# CM41x_M4 register map
Vendor: Analog Devices; Series: CM41x_M4; File version: 1p0
CPU: CM4 r0p1, little endian, MPU, FPU, 4 interrupt priority bits
Registers are 32-bit, read-write, reset 0x0 unless marked. A register's access mark holds for its fields unless they carry their own. Offsets are from the block's base; [hi:lo] are bit positions; {n}, {i} and the like mark numbered series; 'fields as' and 'values as' point back to an identical list.

## TRACE0 — Trace Port Interface Unit
Base 0xE0040000
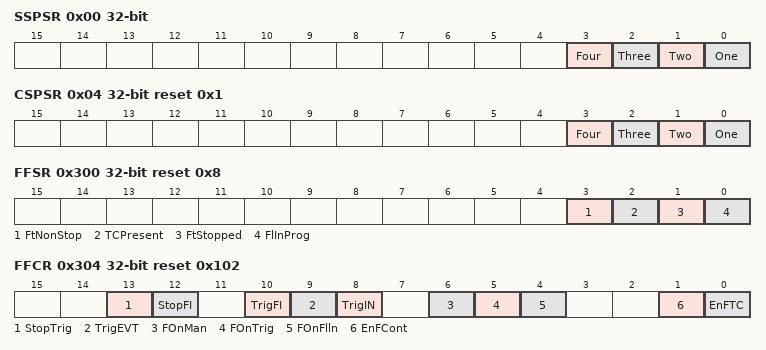
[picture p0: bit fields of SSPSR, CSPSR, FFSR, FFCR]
0x00 SSPSR — Supported Sync Port Sizes Register.
  [3] Four ro — 4-bit port size support
  [2] Three ro — 3-bit port size support
  [1] Two ro — 2-bit port size support
  [0] One ro — 1-bit port size support
0x04 CSPSR reset 0x1 — Current Sync Port Size Register.
  [3] Four range 0x00000000..0x00000001 — 4-bit port enable
  [2] Three range 0x00000000..0x00000001 — 3-bit port enable
  [1] Two range 0x00000000..0x00000001 — 2-bit port enable
  [0] One range 0x00000000..0x00000001 — 1-bit port enable
0x10 ACPR — Async Clock Prescaler Register.
  [12:0] PRESCALER range 0x00000000..0x00001FFF — Divisor for TRACECLKIN is Prescaler + 1.
0xF0 SPPR reset 0x1 — Selected Pin Protocol Register.
  [1:0] PROTOCOL range 0x00000000..0x00000003 — Trace output protocol
0x300 FFSR reset 0x8 — Formatter and Flush Status Register.
  [3] FtNonStop ro — Formatter cannot be stopped
  [2] TCPresent ro — This bit always reads as zero
  [1] FtStopped ro — This bit always reads as zero
  [0] FlInProg ro — This bit always reads as zero
0x304 FFCR reset 0x102 — Formatter and Flush Control Register.
  [13] StopTrig range 0x00000000..0x00000001 — Stop the formatter after a Trigger Event is observed.
  [12] StopFI range 0x00000000..0x00000001 — Stop the formatter after a flush completes.
  [10] TrigFI range 0x00000000..0x00000001 — Indicates a trigger on Flush completion.
  [9] TrigEVT range 0x00000000..0x00000001 — Indicate a trigger on a Trigger Event.
  [8] TrigIN range 0x00000000..0x00000001 — Indicate a trigger on TRIGIN being asserted.
  [6] FOnMan range 0x00000000..0x00000001 — Manually generate a flush of the system.
  [5] FOnTrig range 0x00000000..0x00000001 — Generate flush using Trigger event.
  [4] FOnFlln range 0x00000000..0x00000001 — Generate flush using the FLUSHIN interface.
  [1] EnFCont range 0x00000000..0x00000001 — Continuous Formatting, no TRACECTL.
  [0] EnFTC range 0x00000000..0x00000001 — Enable Formatting.
0x308 FSCR — Formatter Synchronization Counter Register.
  [31:0] VALUE range 0x00000000..0xFFFFFFFF
0xEE8 TRIGGER — Integration Register: TRIGGER.
  [0] TRIGGER_input_value ro — Enables the TRIGGER input
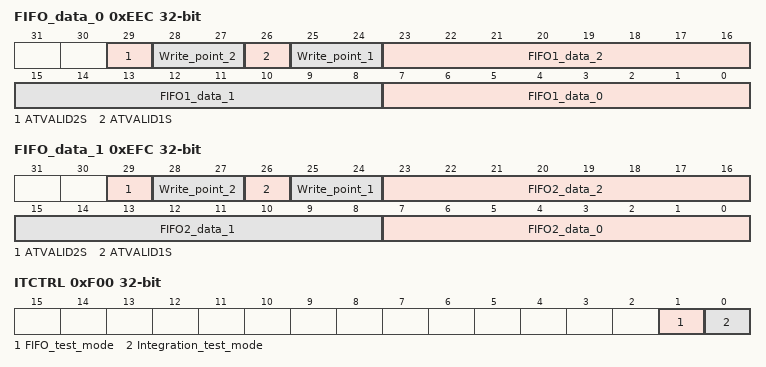
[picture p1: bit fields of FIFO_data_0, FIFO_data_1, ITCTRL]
0xEEC FIFO_data_0 — Integration register: FIFO data 0.
  [29] ATVALID2S ro — Value
  [28:27] Write_point_2 ro
  [26] ATVALID1S ro — Value
  [25:24] Write_point_1 ro
  [23:16] FIFO1_data_2 ro
  [15:8] FIFO1_data_1 ro
  [7:0] FIFO1_data_0 ro
0xEF0 ITATBCTR2 — Integration Register: ITATBCTR2.
  [0] ATREADY1_ATREADY2 ro
0xEF8 ITATBCTR0 — Integration Register: ITATBCTR0.
  [0] ATVALID1_ATVALID2 ro
0xEFC FIFO_data_1 — Integration register: FIFO data 1.
  [29] ATVALID2S ro — Value
  [28:27] Write_point_2 ro
  [26] ATVALID1S ro — Value
  [25:24] Write_point_1 ro
  [23:16] FIFO2_data_2 ro
  [15:8] FIFO2_data_1 ro
  [7:0] FIFO2_data_0 ro
0xF00 ITCTRL — Integration Mode Control Register.
  [1] FIFO_test_mode range 0x00000000..0x00000001 — Enables FIFO test mode
  [0] Integration_test_mode range 0x00000000..0x00000001 — Enables integration test mode
0xFA0 CLAIMSET reset 0xF — Claim tag set register.
  [31:0] VALUE range 0x00000000..0xFFFFFFFF — Claim Tag
0xFA4 CLAIMCLR — Claim tag clear register.
  [31:0] VALUE range 0x00000000..0xFFFFFFFF — Claim Tag
0xFC8 DEVID reset 0xCA1 — Device ID register.
  [31:0] VALUE range 0x00000000..0xFFFFFFFF — Device ID
0xFD0 PID4 reset 0x4 — Peripheral identification register (PID4).
  [31:0] VALUE range 0x00000000..0xFFFFFFFF — Peripheral identification bits
{0xFC0+4i} PID{i} (i=5..7) — Peripheral identification register (PID{i}).
  fields as PID4
0xFE0 PID0 reset 0x23 — Peripheral identification register Bits 7:0 (PID0).
  fields as PID4
0xFE4 PID1 reset 0xB9 — Peripheral identification register Bits 15:8 (PID1).
  fields as PID4
0xFE8 PID2 reset 0x3B — Peripheral identification register Bits 23:16 (PID2).
  fields as PID4
0xFEC PID3 — Peripheral identification register Bits 31:24 (PID3).
  fields as PID4
0xFF0 CID0 reset 0xD — Component identification register Bits 7:0 (CID0).
  [31:0] VALUE range 0x00000000..0xFFFFFFFF — Component Identification Bits
0xFF4 CID1 reset 0x90 — Component identification register Bits 15:8 (CID1).
  fields as CID0
0xFF8 CID2 reset 0x5 — Component identification register Bits 23:16 (CID2).
  fields as CID0
0xFFC CID3 reset 0xB1 — Component identification register Bits 31:24 (CID3).
  fields as CID0
